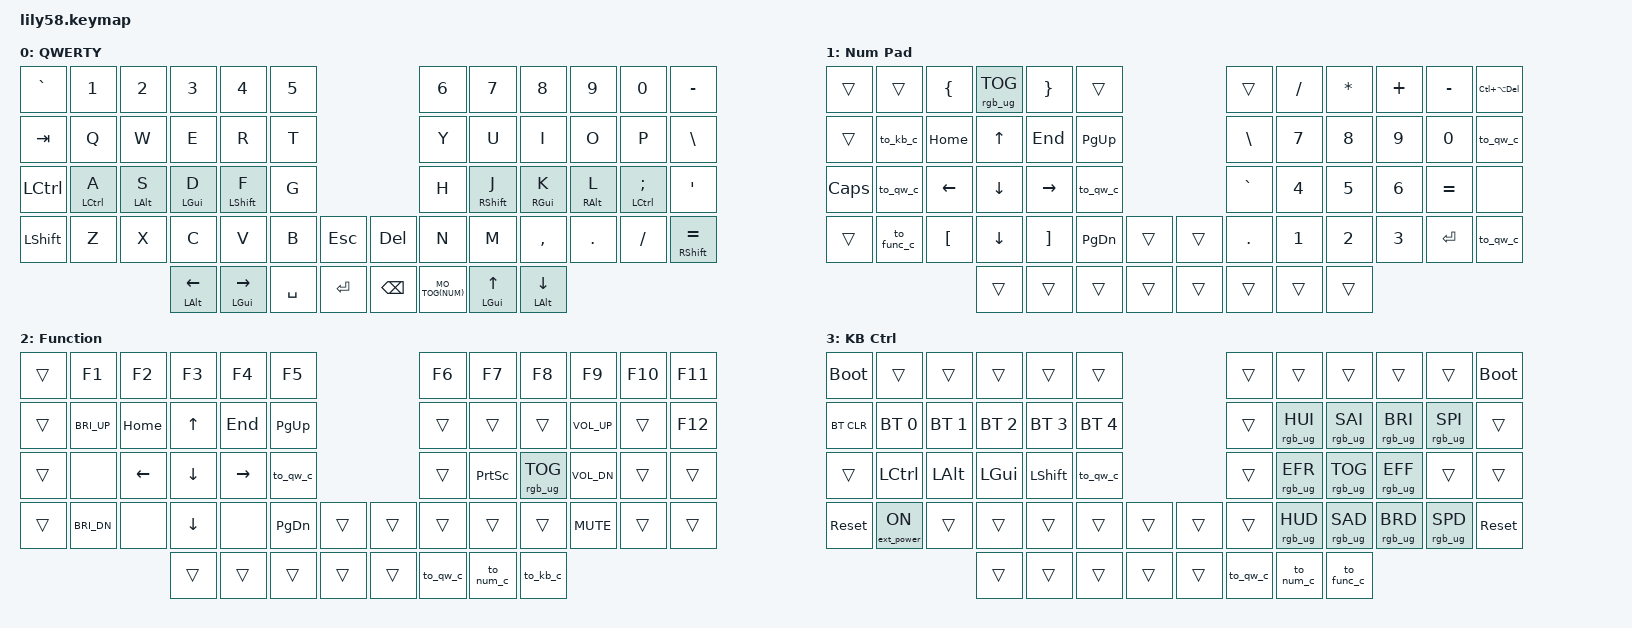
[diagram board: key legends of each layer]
/*
 * Copyright (c) 2020 The ZMK Contributors
 *
 * SPDX-License-Identifier: MIT
 */

/*
 * Lily58 keymap (ZMK), generated from "Lily58 Keybd Layout.xlsx"
 *
 *Designed by and for Amy Hamermesh
 *
 * Binding order for the Lily58 (58 keys per layer):
 *	row 1:	number row			6 + 6
 *	row 2:	QWERTY row			6 + 6
 *	row 3:	home row			6 + 6
 *	row 4:	bottom letter row	6 + inner key, inner key + 6	(14 keys)
 *	row 5:	thumb keys			4 + 4
 *
 * Home-row mods are plain &mt for now (CAGS order, mirrored on both hands):
 *	pinky = Ctrl, ring = Alt/Option, middle = GUI/Cmd, index = Shift.
 * Tune timings and add tap-dance / hold-tap behaviors in the sections below.
 */


#include <behaviors.dtsi>
#include <dt-bindings/zmk/keys.h>
#include <dt-bindings/zmk/bt.h>
#include <dt-bindings/zmk/ext_power.h>
#include <dt-bindings/zmk/rgb.h>

#define QWERTY	0
#define NUM		1
#define FUNC	2
#define KBCTRL	3
#define MO_TOG(layer)	&mo_tog layer layer	// Macro to apply momentary-layer-on-hold/toggle-layer-on-tap to a specific layer

// Layer indicator colors (hue 0-359) and brightness (%) for the non-QWERTY layers
#define HUE_NUM		0	// red
#define HUE_FUNC	120	// green
#define HUE_KB		280	// purple
#define FX_BRT		60


&led_strip {
	chain-length = <35>;
};

&lt {
	tapping-term-ms = <200>;
};

&mt {
	tapping-term-ms = <200>; // This is the value already set by default
};

/ {
	behaviors {
		mo_tog: behavior_mo_tog {
			compatible = "zmk,behavior-hold-tap";
			#binding-cells = <2>;
			flavor = "hold-preferred";
			tapping-term-ms = <200>;
			bindings = <&mo>, <&tog_num_c>;	// hold = plain momentary layer; tap = toggle NUM and set its color
		};

		hm: homerow_mods {
			compatible = "zmk,behavior-hold-tap";
			#binding-cells = <2>;
			flavor = "tap-preferred";
			tapping-term-ms = <280>;
			quick-tap-ms = <175>;
			require-prior-idle-ms = <200>;
			retro-tap;
			bindings = <&kp>, <&kp>;
		};

		hmr: homerow_mods_right {
			compatible = "zmk,behavior-hold-tap";
			#binding-cells = <2>;
			flavor = "balanced";
			tapping-term-ms = <280>;
			quick-tap-ms = <175>;
			require-prior-idle-ms = <200>;
			retro-tap;
			hold-trigger-on-release;
			// Hold only triggers when the next key is on the left hand (incl. left thumbs)
			hold-trigger-key-positions = <0 1 2 3 4 5 12 13 14 15 16 17 24 25 26 27 28 29 36 37 38 39 40 41 42 50 51 52 53>;
			bindings = <&kp>, <&kp>;
		};

		// Shift on the index fingers: gentler than hm/hmr so quick capitals work
		hms: homerow_shift {
			compatible = "zmk,behavior-hold-tap";
			#binding-cells = <2>;
			flavor = "balanced";
			tapping-term-ms = <220>;
			quick-tap-ms = <150>;
			require-prior-idle-ms = <100>;
			retro-tap;
			bindings = <&kp>, <&kp>;
		};

	};

	macros {
		// Layer indicator lighting. QWERTY = swirl (effect 3, multicolor); other layers = solid color.
		// Leaving QWERTY: cycle effect once (swirl -> solid) and set the layer color.
		// Returning to QWERTY: cycle effect 3 times (solid -> breathe -> spectrum -> swirl).
		// Don't use the FX Prv/FX Nxt keys while away from QWERTY or the cycle count will be off.
		// Holding the Num key (momentary) does not change the lights; only toggles and the To keys do.

		tog_num_c: tog_num_c {
			compatible = "zmk,behavior-macro";
			#binding-cells = <0>;
			bindings = <&macro_tap &tog NUM &rgb_ug RGB_EFF &rgb_ug RGB_COLOR_HSB(HUE_NUM,100,FX_BRT)>;
		};

		to_num_c: to_num_c {
			compatible = "zmk,behavior-macro";
			#binding-cells = <0>;
			bindings = <&macro_tap &to NUM &rgb_ug RGB_COLOR_HSB(HUE_NUM,100,FX_BRT)>;
		};

		to_func_c: to_func_c {
			compatible = "zmk,behavior-macro";
			#binding-cells = <0>;
			bindings = <&macro_tap &to FUNC &rgb_ug RGB_COLOR_HSB(HUE_FUNC,100,FX_BRT)>;
		};

		to_kb_c: to_kb_c {
			compatible = "zmk,behavior-macro";
			#binding-cells = <0>;
			bindings = <&macro_tap &to KBCTRL &rgb_ug RGB_COLOR_HSB(HUE_KB,100,FX_BRT)>;
		};

		to_qw_c: to_qw_c {
			compatible = "zmk,behavior-macro";
			#binding-cells = <0>;
			bindings = <&macro_tap &to QWERTY &rgb_ug RGB_EFF &rgb_ug RGB_EFF &rgb_ug RGB_EFF>;
		};
	};

	keymap {
		compatible = "zmk,keymap";

		default_layer {
			display-name = "QWERTY";
//	-------------------------------------------------------------------------------------------------------------------------------------------------------------------------------------
//	|	`		|	1		|	2		|	3		|	4		|	5		|									|	6		|	7		|	8		|	9		|	0		|	-		|
//	|	TAB		|	Q		|	W		|	E		|	R		|	T		|									|	Y		|	U		|	I		|	O		|	P		|	\		|
//	|	LCTRL	|	⌃ A		|	⌥ S		|	⌘ D		|	⇧ F		|	G		|									|	H		|	⇧ J		|	⌘ K		|	⌥ L		|	⌃ ;		|	'		|
//	|	  ⇧ 	|	Z		|	X		|	C		|	V		|	B		|	ESC		|			|	DEL		|	N		|	M		|	,		|	.		|	/		|	⇧/=		|
//										|	⌥ ⬅		|	⌘ ⮕		|	␣		|	ENTER	|			|	BSPC	|	To NUM	|	⌘ ⬆		|	⌥ ⬇		|
			bindings = <
&kp GRAVE	&kp N1		&kp N2		&kp N3			&kp N4			&kp N5							&kp N6		&kp N7			&kp N8			&kp N9		&kp N0			&kp MINUS
&kp TAB		&kp Q		&kp W		&kp E			&kp R			&kp T							&kp Y		&kp U			&kp I			&kp O		&kp P			&kp BSLH
&kp LCTRL	&hm LCTRL A	&hm LALT S	&hm LGUI D		&hms LSHFT F	&kp G							&kp H		&hms RSHFT J	&hmr RGUI K		&hmr RALT L	&hmr LCTRL SEMI	&kp SQT
&kp LSHFT	&kp Z		&kp X		&kp C			&kp V			&kp B		&kp ESC	&kp DEL		&kp N		&kp M			&kp COMMA		&kp DOT		&kp FSLH		&mt RSHFT EQUAL
									&mt LALT LEFT	&mt LGUI RIGHT	&kp SPACE	&kp RET	&kp BSPC	MO_TOG(NUM)	&mt LGUI UP		&mt LALT DOWN
			>;
		};

		number_layer {
			display-name = "Num Pad";
//	-------------------------------------------------------------------------------------------------------------------------------------------------------------------------------------
//	|			|			|	{		|	RGB Tog	|	}		|			|									|			|	/		|	*		|	+		|	-		|	⌃ ⌥ ⌦	|
//	|			|	To KB	|	HOME	|	⬆		|	END		|	PGUP	|									|	\		|	7		|	8		|	9		|	0		|	To QW	|
//	|	CAPS	|	To QW	|	⬅		|	⬇		|	⮕		|	To QW	|									|	`		|	4		|	5		|	6		|	=		|	None	|
//	|			|	To FN	|	[		|	⬇		|	]		|	PGDN	|			|			|			|	.		|	1		|	2		|	3		|	ENTER	|	To QW	|
//										|			|			|			|			|			|			|			|			|			|
			bindings = <
&trans		&trans		&kp LBRC	&rgb_ug RGB_TOG	&kp RBRC	&trans						&trans		&kp FSLH	&kp STAR	&kp PLUS	&kp MINUS	&kp LC(LA(DEL))
&trans		&to_kb_c	&kp HOME	&kp UP			&kp END		&kp PG_UP					&kp BSLH	&kp N7		&kp N8		&kp N9		&kp N0		&to_qw_c
&kp CAPS	&to_qw_c	&kp LEFT	&kp DOWN		&kp RIGHT	&to_qw_c					&kp GRAVE	&kp N4		&kp N5		&kp N6		&kp EQUAL	&none
&trans		&to_func_c	&kp LBKT	&kp DOWN		&kp RBKT	&kp PG_DN	&trans	&trans	&kp DOT		&kp N1		&kp N2		&kp N3		&kp RET		&to_qw_c
									&trans			&trans		&trans		&trans	&trans	&trans		&trans		&trans
			>;
		};

		fn_layer {
			display-name = "Function";
//	-------------------------------------------------------------------------------------------------------------------------------------------------------------------------------------
//	|			|	F1		|	F2		|	F3		|	F4		|	F5		|									|	F6		|	F7		|	F8		|	F9		|	F10		|	F11		|
//	|			|	Disp+	|	HOME	|	⬆		|	END		|	PGUP	|									|			|			|			|	Vol +	|			|	F12		|
//	|			|	None	|	⬅		|	⬇		|	⮕		|	To QW	|									|			|	PRTSC	|	RGB Tog	|	Vol -	|			|			|
//	|			|	Disp-	|	None	|	⬇		|	None	|	PGDN	|			|			|			|			|			|			|	Mute	|			|			|
//										|			|			|			|			|			|			|	To QW	|	To NUM	|	To KB	|
			bindings = <
&trans		&kp F1			&kp F2		&kp F3		&kp F4		&kp F5						&kp F6		&kp F7			&kp F8			&kp F9			&kp F10	&kp F11
&trans		&kp C_BRI_UP	&kp HOME	&kp UP		&kp END		&kp PG_UP					&trans		&trans			&trans			&kp C_VOL_UP	&trans	&kp F12
&trans		&none			&kp LEFT	&kp DOWN	&kp RIGHT	&to_qw_c					&trans		&kp PRINTSCREEN	&rgb_ug RGB_TOG	&kp C_VOL_DN	&trans	&trans
&trans		&kp C_BRI_DN	&none		&kp DOWN	&none		&kp PG_DN	&trans	&trans	&trans		&trans			&trans			&kp C_MUTE		&trans	&trans
										&trans		&trans		&trans		&trans	&trans	&to_qw_c	&to_num_c		&to_kb_c
			>;
		};

		kb_layer {
			display-name = "KB Ctrl";
//	-------------------------------------------------------------------------------------------------------------------------------------------------------------------------------------
//	|	Boot	|			|			|			|			|			|									|			|			|			|			|			|	Boot	|
//	|	BT CLR	|	BT 0	|	BT 1	|	BT 2	|	BT 3	|	BT 4	|									|			|	Hue+	|	Sat+	|	Bri+	|	Spd+	|			|
//	|			|	LCTRL	|	LALT	|	LGUI	|	LSHIFT	|	To QW	|									|			|	FX Prv	|	RGB Tog	|	FX Nxt	|			|			|
//	|	Reset	|	EP On	|			|			|			|			|			|			|			|			|	Hue-	|	Sat-	|	Bri-	|	Spd-	|	Reset	|
//										|			|			|			|			|			|			|	To QW	|	To NUM	|	To FN	|
			bindings = <
&bootloader	&trans				&trans			&trans			&trans			&trans							&trans		&trans			&trans			&trans			&trans			&bootloader
&bt BT_CLR	&bt BT_SEL 0		&bt BT_SEL 1	&bt BT_SEL 2	&bt BT_SEL 3	&bt BT_SEL 4					&trans		&rgb_ug RGB_HUI	&rgb_ug RGB_SAI	&rgb_ug RGB_BRI	&rgb_ug RGB_SPI	&trans
&trans		&kp LCTRL			&kp LALT		&kp LGUI		&kp LSHFT		&to_qw_c						&trans		&rgb_ug RGB_EFR	&rgb_ug RGB_TOG	&rgb_ug RGB_EFF	&trans			&trans
&sys_reset	&ext_power EP_ON	&trans			&trans			&trans			&trans			&trans	&trans	&trans		&rgb_ug RGB_HUD	&rgb_ug RGB_SAD	&rgb_ug RGB_BRD	&rgb_ug RGB_SPD	&sys_reset
												&trans			&trans			&trans			&trans	&trans	&to_qw_c	&to_num_c		&to_func_c
			>;
		};
	};
};
